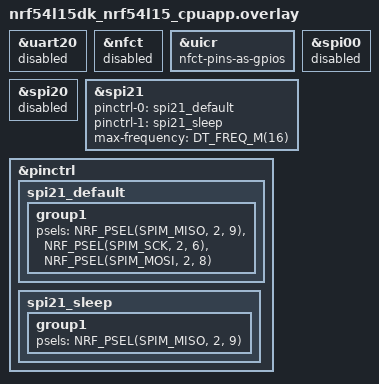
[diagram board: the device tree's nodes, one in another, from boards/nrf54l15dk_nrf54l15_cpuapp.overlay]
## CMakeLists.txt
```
cmake_minimum_required(VERSION 3.20.0)

if(DEFINED CUSTOM_BOILERPLATE)
    include(${CUSTOM_BOILERPLATE})
    return()
endif()

set(COMMON_PATH ${CMAKE_CURRENT_LIST_DIR}/common)
include(${COMMON_PATH}/common.cmake)

GET_DEVICE_CONFIG_FILES(${BOARD} boards)

find_package(Zephyr REQUIRED HINTS $ENV{ZEPHYR_BASE})
project(CGM_Solar_System)
target_sources(app PRIVATE src/main.c)
target_sources(app PRIVATE src/adc.c)
target_include_directories(app PRIVATE common)
target_include_directories(app PRIVATE ${CMAKE_CURRENT_LIST_DIR}/src)
```

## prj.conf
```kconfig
CONFIG_SYSTEM_WORKQUEUE_STACK_SIZE=2048
CONFIG_MAIN_STACK_SIZE=2048

# CGM-only low-power SAADC
CONFIG_NRFX_SAADC=y

# Bluetooth
CONFIG_BT=y
CONFIG_BT_PERIPHERAL=y
CONFIG_BT_MAX_CONN=1

# GATT / MTU
CONFIG_BT_GATT_DYNAMIC_DB=y
CONFIG_BT_GATT_CLIENT=y
CONFIG_BT_L2CAP_TX_MTU=247
CONFIG_BT_BUF_ACL_TX_SIZE=251
CONFIG_BT_BUF_ACL_RX_SIZE=251
CONFIG_BT_RX_STACK_SIZE=2048
CONFIG_BT_GAP_AUTO_UPDATE_CONN_PARAMS=y

# Link update
CONFIG_BT_PHY_UPDATE=y
CONFIG_BT_DATA_LEN_UPDATE=y
CONFIG_BT_USER_DATA_LEN_UPDATE=y
CONFIG_BT_USER_PHY_UPDATE=y
CONFIG_BT_CTLR_PHY_2M=y
CONFIG_BT_CTLR_DATA_LENGTH_MAX=251

# Logging/debug while bring-up
CONFIG_UART_CONSOLE=n
```

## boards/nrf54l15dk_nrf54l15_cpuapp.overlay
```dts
#include "../common/common-pinctrl.dtsi"

&uart20 {
	status = "disabled";
};

&nfct {
	status = "disabled";
};
&uicr {
    nfct-pins-as-gpios;
};

&spi00 {
	status = "disabled";
};
&spi20 {
	status = "disabled";
};
&spi21 {
    status = "okay";
    pinctrl-0 = <&spi21_default>;
    pinctrl-1 = <&spi21_sleep>;
    pinctrl-names = "default", "sleep";
    max-frequency = <DT_FREQ_M(16)>;
};

&pinctrl {
    spi21_default: spi21_default {
        group1 {
            psels = <NRF_PSEL(SPIM_MISO, 2, 9)>,
                    <NRF_PSEL(SPIM_SCK, 2, 6)>,
                    <NRF_PSEL(SPIM_MOSI, 2, 8)>;
        };
    };

    spi21_sleep: spi21_sleep {
        group1 {
            psels = <NRF_PSEL(SPIM_MISO, 2, 9)>;
        };
    };
};
```

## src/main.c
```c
#include "parameter.h"
#include "adc.h"
#include "ble.h"

#define GPIO_LED NRF_GPIO_PIN_MAP(1, 10)

K_MUTEX_DEFINE(adc_cfg_mutex);

// Device 1
#define APP_DEVICE_NAME "CGM_Solar_System_1"
static struct bt_uuid_128 SVC_UUID  = BT_UUID_INIT_128(
    BT_UUID_128_ENCODE(0x4F191C01,0x5A23,0x4A82,0x8F3D,0x6C9E4E9B0110ULL));
static struct bt_uuid_128 TX_UUID= BT_UUID_INIT_128(
    BT_UUID_128_ENCODE(0x4F191C01,0x5A23,0x4A82,0x8F3D,0x6C9E4E9B0111ULL));
static struct bt_uuid_128 RX_UUID= BT_UUID_INIT_128(
    BT_UUID_128_ENCODE(0x4F191C01,0x5A23,0x4A82,0x8F3D,0x6C9E4E9B0112ULL));
// // Device 2
// #define APP_DEVICE_NAME "CGM_Solar_System_2"
// static struct bt_uuid_128 SVC_UUID  = BT_UUID_INIT_128(
//     BT_UUID_128_ENCODE(0x4F191C01,0x5A23,0x4A82,0x8F3D,0x6C9E4E9B0210ULL));
// static struct bt_uuid_128 TX_UUID= BT_UUID_INIT_128(
//     BT_UUID_128_ENCODE(0x4F191C01,0x5A23,0x4A82,0x8F3D,0x6C9E4E9B0211ULL));
// static struct bt_uuid_128 RX_UUID= BT_UUID_INIT_128(
//     BT_UUID_128_ENCODE(0x4F191C01,0x5A23,0x4A82,0x8F3D,0x6C9E4E9B0212ULL));

static struct bt_conn *current_conn;
static atomic_t g_ccc_on = ATOMIC_INIT(0);
static struct k_work_delayable phy_update_work;
static struct bt_conn *phy_update_conn;
static struct k_work_delayable adv_restart_work;
static atomic_t adv_restart_armed = ATOMIC_INIT(0);

static ssize_t tx_read(struct bt_conn *conn, const struct bt_gatt_attr *attr, void *buf, uint16_t len, uint16_t offset)
{
    uint32_t zero = 0;
    return bt_gatt_attr_read(conn, attr, buf, len, offset, &zero, sizeof(zero));
}

static ssize_t rx_write(struct bt_conn *conn, const struct bt_gatt_attr *attr, const void *buf, uint16_t len, uint16_t offset, uint8_t flags)
{
    const uint8_t *p = (const uint8_t *)buf;
    uint16_t i = 0;
	bool changed = false;

    struct adc_config_struct new_cfg;
    {
        unsigned int key = irq_lock();
        new_cfg = g_cfg;
        irq_unlock(key);
    }

    while (i + 2 <= len) {
        uint8_t cmd = p[i++], L = p[i++];
        if (i + L > len) break;
        switch (cmd) {
        case CMD_SAMPLE_RATE_SPS:
            if (L >= 1) {
                uint8_t sps = p[i];
                if (sps < CGM_SAMPLE_RATE_SPS_MIN) {
                    sps = CGM_SAMPLE_RATE_SPS_MIN;
                }
                if (sps > CGM_SAMPLE_RATE_SPS_MAX) {
                    sps = CGM_SAMPLE_RATE_SPS_MAX;
                }
                new_cfg.sample_rate_sps = sps;
                new_cfg.sample_period_ms = (sps >= 2u) ? CGM_PERIOD_MS_2SPS : CGM_PERIOD_MS_1SPS;
                changed = true;
            }
            break;


        default: break;
        }
        i += L;
    }

    if (changed) {
        unsigned int key = irq_lock();
        g_cfg = new_cfg;
        irq_unlock(key);
        k_mutex_lock(&adc_cfg_mutex, K_FOREVER);
        g_cfg = new_cfg;
        k_mutex_unlock(&adc_cfg_mutex);
        adc_apply_config(&g_cfg);
    }

    return len;	
}

static void tx_ccc_changed(const struct bt_gatt_attr *attr, uint16_t value)
{
    bool on = (value & (STREAM_USE_INDICATE ? BT_GATT_CCC_INDICATE : BT_GATT_CCC_NOTIFY)) != 0;
    atomic_set(&g_ccc_on, on);
}

#if defined(CONFIG_BT)
static uint8_t dummy_readback;
BT_GATT_SERVICE_DEFINE(cgm_svc,
        BT_GATT_PRIMARY_SERVICE(&SVC_UUID),
        BT_GATT_CHARACTERISTIC(&TX_UUID.uuid,
#if             STREAM_USE_INDICATE
                BT_GATT_CHRC_READ | BT_GATT_CHRC_INDICATE,
#else
                BT_GATT_CHRC_READ | BT_GATT_CHRC_NOTIFY,
#endif
                BT_GATT_PERM_READ, tx_read, NULL, &dummy_readback),
        BT_GATT_CCC(tx_ccc_changed, BT_GATT_PERM_READ | BT_GATT_PERM_WRITE),
        BT_GATT_CHARACTERISTIC(&RX_UUID.uuid,
                BT_GATT_CHRC_WRITE | BT_GATT_CHRC_WRITE_WITHOUT_RESP,
                BT_GATT_PERM_WRITE, NULL, rx_write, NULL),
);
#endif

#if defined(CONFIG_BT_PHY_UPDATE)
static void phy_update_work_handler(struct k_work *work)
{
    ARG_UNUSED(work);
    if (!phy_update_conn) return;
    const struct bt_conn_le_phy_param pref = {
        .options     = BT_CONN_LE_PHY_OPT_NONE,
        .pref_rx_phy = BT_GAP_LE_PHY_2M,
        .pref_tx_phy = BT_GAP_LE_PHY_2M,
    };
    bt_conn_le_phy_update(phy_update_conn, &pref);
    bt_conn_unref(phy_update_conn);
    phy_update_conn = NULL;
}
#endif

static int adv_start(void);

static void adv_restart_work_handler(struct k_work *work)
{
    ARG_UNUSED(work);
    atomic_set(&adv_restart_armed, 0);

    (void)bt_le_adv_stop();

    int rc = adv_start();
    if (rc) {
        if (atomic_cas(&adv_restart_armed, 0, 1)) {
            k_work_schedule(&adv_restart_work, K_MSEC(300));
        }
    }
}

static inline void adv_restart_request(k_timeout_t delay)
{
    if (atomic_cas(&adv_restart_armed, 0, 1)) {
        k_work_schedule(&adv_restart_work, delay);
    }
}

static void connected(struct bt_conn *conn, uint8_t err)
{
    if (err) {
        adv_restart_request(K_NO_WAIT);
        return;
    }
    current_conn = bt_conn_ref(conn);

#if defined(CONFIG_BT_PHY_UPDATE)
    if (phy_update_conn) {
        bt_conn_unref(phy_update_conn);
        phy_update_conn = NULL;
    }
    phy_update_conn = bt_conn_ref(conn);
    k_work_schedule(&phy_update_work, K_MSEC(200));
#endif

    struct bt_le_conn_param param = {
        .interval_min	= REQ_CONN_INTERVAL_MIN,
        .interval_max	= REQ_CONN_INTERVAL_MAX,
        .latency        = REQ_CONN_LATENCY,
        .timeout        = REQ_CONN_TIMEOUT,
    };
    bt_conn_le_param_update(conn, &param);

    int i = 0;
    while(i < 5) {
        nrf_gpio_cfg_output(GPIO_LED);
        nrf_gpio_pin_set(GPIO_LED);
        k_sleep(K_MSEC(200));
        nrf_gpio_pin_clear(GPIO_LED);
        k_sleep(K_MSEC(200));
        nrf_gpio_cfg_default(GPIO_LED);
        i++;
    }
}

static void disconnected(struct bt_conn *conn, uint8_t reason)
{
    ARG_UNUSED(reason);
    if (current_conn) { bt_conn_unref(current_conn); current_conn = NULL; }
    atomic_set(&g_ccc_on, 0);
    adv_restart_request(K_NO_WAIT);
}

BT_CONN_CB_DEFINE(conn_callbacks) = {
    .connected = connected,
    .disconnected = disconnected,
};

static const struct bt_gatt_attr *tx_attr(void) { return &cgm_svc.attrs[2]; }

#define WORK_STACK_SZ 4096
K_THREAD_STACK_DEFINE(work_stack_area, WORK_STACK_SZ);
static struct k_thread work_thread_data;
static k_tid_t work_tid;

static void work_thread(void *a, void *b, void *c)
{
    ARG_UNUSED(a); ARG_UNUSED(b); ARG_UNUSED(c);

    static uint8_t buf[64];

    for (;;) {
        if (!current_conn || !atomic_get(&g_ccc_on)) {
            k_sleep(K_MSEC(1000));
            continue;
        }

        uint16_t mtu = bt_gatt_get_mtu(current_conn);
        if (mtu < 23) {
            mtu = 23;
        }

        uint16_t payload = (mtu - 3);
        if (payload > sizeof(buf)) {
            payload = sizeof(buf);
        }
        if (payload > MAX_NOTIFY_PAYLOAD_BYTES) {
            payload = MAX_NOTIFY_PAYLOAD_BYTES;
        }

        bool sent_any = false;

#if STREAM_USE_INDICATE
        static struct bt_gatt_indicate_params ip = {0};
        ip.attr = tx_attr();

        for (;;) {
            size_t n = adc_fill_chunk(buf, payload);
            if (!n) {
                break;
            }

            ip.data = buf;
            ip.len  = (uint16_t)n;
            int rc = bt_gatt_indicate(current_conn, &ip);
            if (rc == 0) {
                sent_any = true;
                continue;
            }
            if (rc == -ENOMEM) {
                break;
            }
            break;
        }
#else
        for (;;) {
            size_t n = adc_fill_chunk(buf, payload);
            if (!n) {
                break;
            }

            struct bt_gatt_notify_params np = {
                .attr = tx_attr(),
                .data = buf,
                .len  = (uint16_t)n,
            };
            int rc = bt_gatt_notify_cb(current_conn, &np);
            if (rc == 0) {
                sent_any = true;
                continue;
            }
            if (rc == -ENOMEM) {
                break;
            }
            break;
        }
#endif

        k_sleep(sent_any ? K_MSEC(500) : K_MSEC(10));
    }
}

static int adv_start(void)
{
    struct bt_data ad[] = {
        BT_DATA_BYTES(BT_DATA_FLAGS, (BT_LE_AD_GENERAL | BT_LE_AD_NO_BREDR)),
        BT_DATA(BT_DATA_UUID128_ALL, SVC_UUID.val, sizeof(SVC_UUID.val))
    };
    struct bt_data sd[] = {
        BT_DATA(BT_DATA_NAME_COMPLETE, APP_DEVICE_NAME, strlen(APP_DEVICE_NAME)),
    };
    return bt_le_adv_start(BT_LE_ADV_CONN_FAST_1, ad, ARRAY_SIZE(ad), sd, ARRAY_SIZE(sd));
}

int main(void)
{
    adc_init();

    int i = 0;
    while(i < 3) {
        nrf_gpio_cfg_output(GPIO_LED);
        nrf_gpio_pin_set(GPIO_LED);
        k_sleep(K_MSEC(200));
        nrf_gpio_pin_clear(GPIO_LED);
        k_sleep(K_MSEC(200));
        nrf_gpio_cfg_default(GPIO_LED);
        i++;
    }
    
    (void)bt_set_name(APP_DEVICE_NAME);
    bt_enable(NULL);
    k_work_init_delayable(&adv_restart_work, adv_restart_work_handler);
#if defined(CONFIG_BT_PHY_UPDATE)
    k_work_init_delayable(&phy_update_work, phy_update_work_handler);
    phy_update_conn = NULL;
#endif

    if (adv_start()) {
        adv_restart_request(K_MSEC(1000));
    }

    if (work_tid) return 0;
    work_tid = k_thread_create(&work_thread_data, work_stack_area, K_THREAD_STACK_SIZEOF(work_stack_area),
                               work_thread, NULL, NULL, NULL, K_PRIO_PREEMPT(4), 0, K_NO_WAIT);
    k_thread_name_set(work_tid, "work");

    while (1) {
        k_sleep(K_FOREVER);
    }
}
```

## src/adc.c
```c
#include "parameter.h"
#include "adc.h"

struct adc_config_struct g_cfg;
extern struct k_mutex adc_cfg_mutex;

static const nrfx_saadc_channel_t m_channels[] = {
    SAADC_CHANNEL_SE_ACQ(CH0_AIN, NULL, 0, 1),
};
static int16_t s_saadc_buf[2];

struct packet_node {
    void *fifo_reserved;
    uint16_t len;
    uint8_t bytes[sizeof(struct cgm_feature_packet)];
};

K_FIFO_DEFINE(g_free_fifo);
K_FIFO_DEFINE(g_filled_fifo);
static struct packet_node g_packet_pool[PACKET_POOL_SIZE];

static struct k_work_delayable s_cgm_sample_work;
static uint16_t s_packet_seq = 0;
static atomic_t s_saadc_irq_connected = ATOMIC_INIT(0);

static volatile int s_saadc_last_status = 0;

static inline uint16_t sample_rate_to_period_ms(uint8_t sps)
{
    return (sps >= 2u) ? CGM_PERIOD_MS_2SPS : CGM_PERIOD_MS_1SPS;
}

static struct adc_config_struct adc_cfg_snapshot(void)
{
    unsigned int key = irq_lock();
    struct adc_config_struct cfg = g_cfg;
    irq_unlock(key);
    return cfg;
}

static inline void saadc_scan_once(uint16_t *out, int n_ch)
{
    nrfx_saadc_mode_trigger();
    for (int i = 0; i < n_ch; ++i) {
        out[i] = (uint16_t)(s_saadc_buf[i] & 0x0FFF);
    }
}

static void queue_packet(uint8_t flags, uint16_t raw_avg)
{
    struct packet_node *node = k_fifo_get(&g_free_fifo, K_NO_WAIT);
    if (!node) {
        node = k_fifo_get(&g_filled_fifo, K_NO_WAIT);
        if (!node) {
            return;
        }
    }

    struct adc_config_struct cfg = adc_cfg_snapshot();

    struct cgm_feature_packet pkt;
    memset(&pkt, 0, sizeof(pkt));
    pkt.magic = 0xA5u;
    pkt.version = 2u;
    pkt.flags = flags;
    pkt.sample_rate_sps = cfg.sample_rate_sps;
    pkt.seq = s_packet_seq++;
    pkt.tick_ms = k_uptime_get_32();
    pkt.raw_avg = raw_avg;

    memcpy(node->bytes, &pkt, sizeof(pkt));
    node->len = sizeof(pkt);
    k_fifo_put(&g_filled_fifo, node);
}

static void queue_cgm_packet(uint16_t raw_avg)
{
    queue_packet(0x01u, raw_avg);
}

static void cgm_sample_work_handler(struct k_work *work)
{
    ARG_UNUSED(work);
    nrfx_saadc_init(NRFX_SAADC_DEFAULT_CONFIG_IRQ_PRIORITY);
    nrfx_saadc_channel_config(m_channels);
    nrfx_saadc_simple_mode_set((1UL << 0), ADC_RESOLUTION, NRF_SAADC_OVERSAMPLE_DISABLED, NULL);
    nrfx_saadc_buffer_set(s_saadc_buf, 1);
    nrfx_saadc_offset_calibrate(NULL);

    uint16_t raw[1];
    uint32_t sum0 = 0;
    for (int i = 0; i < SAMPLING_ITERATIONS; ++i) {
        saadc_scan_once(raw, 1);
        sum0 += raw[0];
    }
    uint16_t avg_raw0 = (uint16_t)(sum0 / SAMPLING_ITERATIONS);
    nrfx_saadc_uninit();

    queue_cgm_packet(avg_raw0);

    struct adc_config_struct cfg = adc_cfg_snapshot();
    uint16_t period_ms = cfg.sample_period_ms;
    if (period_ms == 0u) {
        period_ms = sample_rate_to_period_ms(CGM_SAMPLE_RATE_SPS_DEFAULT);
    }

    k_work_schedule(&s_cgm_sample_work, K_MSEC(period_ms));
}

void adc_init(void)
{
#if defined(__ZEPHYR__)
    if (atomic_cas(&s_saadc_irq_connected, 0, 1)) {
        IRQ_CONNECT(NRFX_IRQ_NUMBER_GET(NRF_SAADC), IRQ_PRIO_LOWEST,
                    nrfx_saadc_irq_handler, 0, 0);
    }
#endif

    unsigned int key = irq_lock();
    g_cfg.sample_rate_sps = CGM_SAMPLE_RATE_SPS_DEFAULT;
    g_cfg.avg_samples = CGM_BURST_SAMPLES_DEFAULT;
    g_cfg.sample_period_ms = sample_rate_to_period_ms(CGM_SAMPLE_RATE_SPS_DEFAULT);
    irq_unlock(key);

    for (int i = 0; i < PACKET_POOL_SIZE; ++i) {
        g_packet_pool[i].len = 0;
        k_fifo_put(&g_free_fifo, &g_packet_pool[i]);
    }

    k_work_init_delayable(&s_cgm_sample_work, cgm_sample_work_handler);
    k_work_schedule(&s_cgm_sample_work, K_MSEC(g_cfg.sample_period_ms));
}

void adc_apply_config(const struct adc_config_struct *cfg)
{
    struct adc_config_struct new_cfg = *cfg;

    if (new_cfg.sample_rate_sps < CGM_SAMPLE_RATE_SPS_MIN) {
        new_cfg.sample_rate_sps = CGM_SAMPLE_RATE_SPS_MIN;
    }
    if (new_cfg.sample_rate_sps > CGM_SAMPLE_RATE_SPS_MAX) {
        new_cfg.sample_rate_sps = CGM_SAMPLE_RATE_SPS_MAX;
    }
    if (new_cfg.avg_samples == 0u) {
        new_cfg.avg_samples = CGM_BURST_SAMPLES_DEFAULT;
    }
    new_cfg.sample_period_ms = sample_rate_to_period_ms(new_cfg.sample_rate_sps);

    unsigned int key = irq_lock();
    g_cfg = new_cfg;
    irq_unlock(key);

    k_work_reschedule(&s_cgm_sample_work, K_MSEC(new_cfg.sample_period_ms));
}

void adc_set_sample_rate_sps(uint8_t sps)
{
    struct adc_config_struct cfg = adc_cfg_snapshot();
    cfg.sample_rate_sps = sps;
    adc_apply_config(&cfg);
}

size_t adc_fill_chunk(uint8_t *dst, size_t max_len)
{
    struct packet_node *ck = k_fifo_get(&g_filled_fifo, K_NO_WAIT);
    if (!ck) {
        return 0;
    }

    size_t n = ck->len;
    if (n > max_len) {
        n = max_len;
    }
    memcpy(dst, ck->bytes, n);

    k_fifo_put(&g_free_fifo, ck);
    return n;
}
```

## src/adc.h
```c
#ifndef ADC_H__
#define ADC_H__

#define CH0_AIN 0

#define SAADC_CHANNEL_SE_ACQ(_pin_p, _pin_n, _index, _mode)            \
{                                                                      \
    .channel_config =                                                  \
    {                                                                  \
        NRFX_COND_CODE_1(NRF_SAADC_HAS_CH_CONFIG_RES,                  \
                         (.resistor_p = NRF_SAADC_RESISTOR_DISABLED,   \
                          .resistor_n = NRF_SAADC_RESISTOR_DISABLED,), \
                        ())                                            \
        .gain       = NRF_SAADC_GAIN2_7,                               \
        .reference  = NRF_SAADC_REFERENCE_INTERNAL,                    \
        NRFX_COND_CODE_1(NRF_SAADC_HAS_ACQTIME_ENUM,                   \
                         (.acq_time = NRF_SAADC_ACQTIME_20US,),        \
                         (.acq_time = 20,))                            \
        .mode       = NRF_SAADC_MODE_SINGLE_ENDED,                     \
        .burst      = NRF_SAADC_BURST_DISABLED,                        \
    },                                                                 \
    .pin_p          = (nrfx_analog_input_t)_pin_p,                     \
    .pin_n          = NRFX_ANALOG_INPUT_DISABLED,                      \
    .channel_index  = _index,                                          \
}

#define ADC_RESOLUTION                 NRF_SAADC_RESOLUTION_12BIT
#define ADC_12BIT_MAX_CODE             4095
#define SAMPLING_ITERATIONS            10
#define CGM_BURST_SAMPLES_DEFAULT      1u
#define CGM_BURST_SAMPLE_GAP_MS        2u
#define CGM_SAMPLE_RATE_SPS_DEFAULT    1u
#define CGM_SAMPLE_RATE_SPS_MIN        1u
#define CGM_SAMPLE_RATE_SPS_MAX        2u
#define CGM_PERIOD_MS_1SPS             1000u
#define CGM_PERIOD_MS_2SPS             500u
#define PACKET_POOL_SIZE               4
#define MAX_NOTIFY_PAYLOAD_BYTES       200
#define CMD_SAMPLE_RATE_SPS            0x10u

#pragma pack(push, 1)
struct adc_config_struct {
    uint8_t  sample_rate_sps;
    uint8_t  avg_samples;
    uint16_t sample_period_ms;
};

struct cgm_feature_packet {
    uint8_t  magic;
    uint8_t  version;
    uint8_t  flags;
    uint8_t  sample_rate_sps;
    uint16_t seq;
    uint32_t tick_ms;
    uint16_t raw_avg;
};
#pragma pack(pop)

void adc_init(void);
void adc_apply_config(const struct adc_config_struct *cfg);
void adc_set_sample_rate_sps(uint8_t sps);
size_t adc_fill_chunk(uint8_t *dst, size_t max_len);

extern struct adc_config_struct g_cfg;

#endif /* ADC_H__ */
```

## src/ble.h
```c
#ifndef BLE_H__
#define BLE_H__

#include "parameter.h"

/* 0: Notify, 1: Indicate */
#define STREAM_USE_INDICATE 0
#define MAX_NOTIFY_PAYLOAD_BYTES 200

/* ==== Advertising name ==== */
#define APP_DEVICE_NAME_LEN (sizeof(APP_DEVICE_NAME) - 1)

#define APP_BLE_CONN_CFG_TAG    1
#define APP_BLE_OBSERVER_PRIO   3
#define NUS_SERVICE_UUID_TYPE   BLE_UUID_TYPE_VENDOR_BEGIN

#define APP_ADV_INTERVAL    640
#define APP_ADV_DURATION    18000

/* CGM-only traffic is 1 or 2 short packets/s.
 * Longer BLE interval reduces radio wakeups compared with 7.5~11.25 ms.
 * Units: 1.25 ms.
 * 80  = 100 ms
 * 160 = 200 ms
 */
#define REQ_CONN_INTERVAL_MIN 80
#define REQ_CONN_INTERVAL_MAX 160
#define REQ_CONN_LATENCY      4
#define REQ_CONN_TIMEOUT      400

#define DEAD_BEEF           0xDEADBEEF

#define UART_TX_BUF_SIZE    256
#define UART_RX_BUF_SIZE    256

#endif // BLE_H__
```

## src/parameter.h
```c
#ifndef PARAMETER_H__
#define PARAMETER_H__
#include "boards/nrf54l15dk_nrf54l15_config.h"

#include <stdint.h>
#include <stddef.h>
#include <string.h>
#include <stdio.h>
#include <errno.h>
#include <stdatomic.h>
#include <stdbool.h>

#include <zephyr/types.h>
#include <zephyr/sys/printk.h>
#include <zephyr/sys/byteorder.h>
#include <zephyr/settings/settings.h>
#include <zephyr/kernel.h>

#include <hal/nrf_gpio.h>
#include <hal/nrf_saadc.h>
#include <nrfx_saadc.h>

#include <zephyr/bluetooth/bluetooth.h>
#include <zephyr/bluetooth/hci.h>
#include <zephyr/bluetooth/conn.h>
#include <zephyr/bluetooth/uuid.h>
#include <zephyr/bluetooth/gatt.h>

#endif /* PARAMETER_H__ */
```
